# USCI_B1__I2C_Mode_2 register map
Vendor: Texas Instruments
Peripheral module from a debugger description file (folder msp430).
Registers are 8-bit, access not given, no defined reset value unless marked. A register's access mark holds for its fields unless they carry their own. Offsets are as the file gives them; lines under a group give offsets from that group; [hi:lo] are bit positions; {n}, {i} and the like mark numbered series; 'fields as' and 'values as' point back to an identical list; <NAME> marks a mode.

## USCI_B1_I2C_Mode
0x620 UCB1CTLW0 16-bit — USCI B1 Control Word Register 0
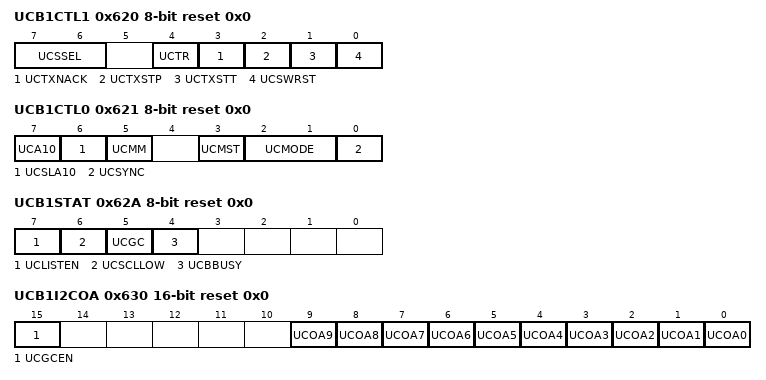
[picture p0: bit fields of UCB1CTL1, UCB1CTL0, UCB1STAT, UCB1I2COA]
0x620 UCB1CTL1 rw reset 0x0 — USCI B1 Control Register 1
  [7:6] UCSSEL — USCI 1 Clock Source Select 1
    {v}=USCI 0 Clock Source: {v} (v=0..3)
  [4] UCTR — Transmit/Receive Select/Flag
  [3] UCTXNACK — Transmit NACK
  [2] UCTXSTP — Transmit STOP
  [1] UCTXSTT — Transmit START
  [0] UCSWRST — USCI Software Reset
0x621 UCB1CTL0 rw reset 0x0 — USCI B1 Control Register 0
  [7] UCA10 — 10-bit Address Mode
  [6] UCSLA10 — 10-bit Slave Address Mode
  [5] UCMM — Multi-Master Environment
  [3] UCMST — Sync. Mode: Master Select
  [2:1] UCMODE — Sync. Mode: USCI Mode 1
    {v}=Sync. Mode: USCI Mode: {v} (v=0..3)
  [0] UCSYNC — Sync-Mode 0:UART-Mode / 1:SPI-Mode
0x626 UCB1BRW 16-bit — USCI B1 Baud Word Rate 0
0x626 UCB1BR0 — USCI B1 Baud Rate 0
0x627 UCB1BR1 — USCI B1 Baud Rate 1
0x62A UCB1STAT rw reset 0x0 — USCI B1 Status Register
  [7] UCLISTEN — USCI Listen mode
  [6] UCSCLLOW — SCL low
  [5] UCGC — General Call address received Flag
  [4] UCBBUSY — Bus Busy Flag
0x62C UCB1RXBUF — USCI B1 Receive Buffer
0x62E UCB1TXBUF — USCI B1 Transmit Buffer
0x630 UCB1I2COA 16-bit rw reset 0x0 — USCI B1 I2C Own Address
  [15] UCGCEN — I2C General Call enable
  [n] UCOA{n} (n=0..9) — I2C Own Address {n}
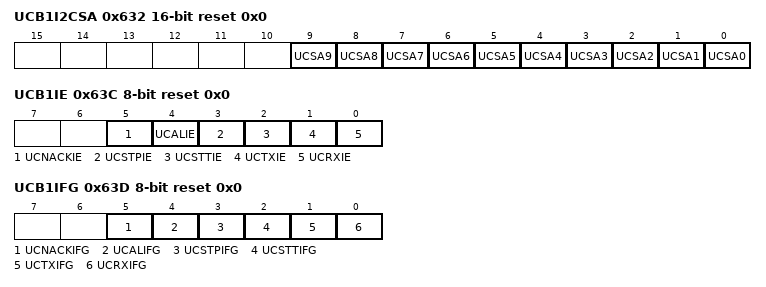
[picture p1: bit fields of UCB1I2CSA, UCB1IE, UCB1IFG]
0x632 UCB1I2CSA 16-bit rw reset 0x0 — USCI B1 I2C Slave Address
  [n] UCSA{n} (n=0..9) — I2C Slave Address {n}
0x63C UCB1ICTL 16-bit — USCI B1 Interrupt Enable Register
0x63C UCB1IE rw reset 0x0 — USCI B1 Interrupt Enable Register
  [5] UCNACKIE — NACK Condition interrupt enable
  [4] UCALIE — Arbitration Lost interrupt enable
  [3] UCSTPIE — STOP Condition interrupt enable
  [2] UCSTTIE — START Condition interrupt enable
  [1] UCTXIE — USCI Transmit Interrupt Enable
  [0] UCRXIE — USCI Receive Interrupt Enable
0x63D UCB1IFG rw reset 0x0 — USCI B1 Interrupt Flags Register
  [5] UCNACKIFG — NAK Condition interrupt Flag
  [4] UCALIFG — Arbitration Lost interrupt Flag
  [3] UCSTPIFG — STOP Condition interrupt Flag
  [2] UCSTTIFG — START Condition interrupt Flag
  [1] UCTXIFG — USCI Transmit Interrupt Flag
  [0] UCRXIFG — USCI Receive Interrupt Flag
0x63E UCB1IV 16-bit — USCI B1 Interrupt Vector Register
